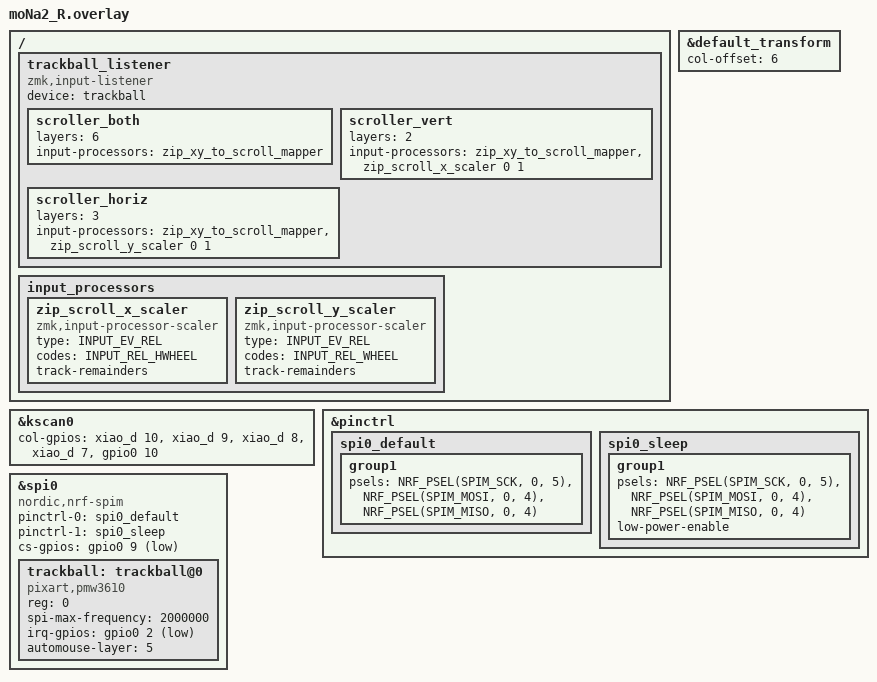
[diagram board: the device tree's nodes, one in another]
#include "moNa2.dtsi" 
#include <input/processors.dtsi>
#include <zephyr/dt-bindings/input/input-event-codes.h>

&default_transform {
    col-offset = <6>;
};

&kscan0 {
        col-gpios
            = <&xiao_d 10 GPIO_ACTIVE_HIGH>
            , <&xiao_d 9 GPIO_ACTIVE_HIGH> 
            , <&xiao_d 8 GPIO_ACTIVE_HIGH> 
            , <&xiao_d 7 GPIO_ACTIVE_HIGH> 
            , <&gpio0 10 GPIO_ACTIVE_HIGH>
            ;
};

/ {
    trackball_listener: trackball_listener {
        compatible = "zmk,input-listener";
        device = <&trackball>;

        /* レイヤ6: 縦＋横スクロール（今までの 6 と同じ挙動） */
        scroller_both {
            layers = <6>;
            input-processors = <
                &zip_xy_to_scroll_mapper
            >;
        };

        /* レイヤ2: 縦スクロールのみ（横を0倍にして殺す） */
        scroller_vert {
            layers = <2>;
            input-processors = <
                &zip_xy_to_scroll_mapper
                &zip_scroll_x_scaler 0 1   /* HWHEEL を 0 倍 → 縦だけ残る */
            >;
        };

        /* レイヤ3: 横スクロールのみ（縦を0倍にして殺す） */
        scroller_horiz {
            layers = <3>;
            input-processors = <
                &zip_xy_to_scroll_mapper
                &zip_scroll_y_scaler 0 1   /* WHEEL を 0 倍 → 横だけ残る */
            >;
        };
    };

    /* スクロール用スケーラ定義 */
    input_processors {
        zip_scroll_x_scaler: zip_scroll_x_scaler {
            compatible = "zmk,input-processor-scaler";
            #input-processor-cells = <2>;
            type = <INPUT_EV_REL>;
            codes = <INPUT_REL_HWHEEL>;
            track-remainders;
        };

        zip_scroll_y_scaler: zip_scroll_y_scaler {
            compatible = "zmk,input-processor-scaler";
            #input-processor-cells = <2>;
            type = <INPUT_EV_REL>;
            codes = <INPUT_REL_WHEEL>;
            track-remainders;
        };
    };
};

&pinctrl {
    spi0_default: spi0_default {
        group1 {
            psels = <NRF_PSEL(SPIM_SCK, 0, 5)>,
                <NRF_PSEL(SPIM_MOSI, 0, 4)>,
                <NRF_PSEL(SPIM_MISO, 0, 4)>;
        };
    };

    spi0_sleep: spi0_sleep {
        group1 {
            psels = <NRF_PSEL(SPIM_SCK, 0, 5)>,
                <NRF_PSEL(SPIM_MOSI, 0, 4)>,
                <NRF_PSEL(SPIM_MISO, 0, 4)>;
            low-power-enable;
        };
    };
};

&spi0 {
    status = "okay";
    compatible = "nordic,nrf-spim";
    pinctrl-0 = <&spi0_default>;
    pinctrl-1 = <&spi0_sleep>;
    pinctrl-names = "default", "sleep";
    cs-gpios = <&gpio0 9 GPIO_ACTIVE_LOW>;

    trackball: trackball@0 {
        status = "okay";
        compatible = "pixart,pmw3610";
        reg = <0>;
        spi-max-frequency = <2000000>;
        irq-gpios = <&gpio0 2 (GPIO_ACTIVE_LOW | GPIO_PULL_UP)>;

        automouse-layer = <5>;

        /* ★ ドライバ側スクロールは使わないのでコメントアウトする */
        /* scroll-layers = <6>; */
    };
};
